# AC30M1X64 register map
Vendor: ABOV Semiconductor Co., Ltd.; File version: 1.0.0
CPU: CM0 r1p0, little endian, no MPU, no FPU, 2 interrupt priority bits
Registers are 32-bit, read-write, reset 0x0 unless marked. A register's access mark holds for its fields unless they carry their own. Offsets are from the block's base; [hi:lo] are bit positions; {n}, {i} and the like mark numbered series; 'fields as' and 'values as' point back to an identical list.

## SP — SERIAL PERIPHERAL INTERFACE
Base 0x40009000
0x00 RDR ro (reset mask 0xFFFF) — SPI n Receive Data Register
  [16:0] RDR — Data
0x00 TDR wo (reset mask 0xFFFF) — SPI n Transmit Data Register
  [16:0] TDR — Data
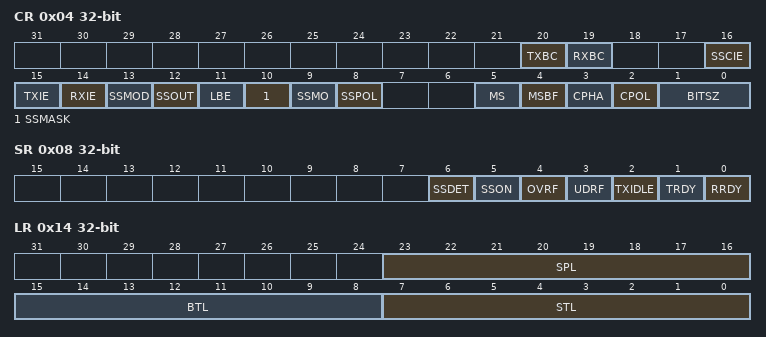
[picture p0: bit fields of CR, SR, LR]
0x04 CR — SPI n Control Register
  [20] TXBC — Tx buffer clear bit
  [19] RXBC — Rx buffer clear bit
  [16] SSCIE — SSn Edge Change Interrupt enable bit
  [15] TXIE — Transmit interrupt enable bit
  [14] RXIE — Receive interrupt enable bit
  [13] SSMOD — SS Auto/Manual Output select bit
  [12] SSOUT — SS output signal select bit
  [11] LBE — Loop-back mode select bit in master mode
  [10] SSMASK — SS Signal masking bit in slave mode
  [9] SSMO — SS output signal select bit
  [8] SSPOL — SS Signal polarity select bit
  [5] MS — master/slaver select bit
  [4] MSBF — MSB/LSB transmit select bit
  [3] CPHA — SPI clock phase bit
  [2] CPOL — SPI clock polarity bit
  [1:0] BITSZ — Transmit/receive Data bits select bit
0x08 SR — SPI n Status Register
  [6] SSDET — The rising edge of SS detect flag
  [5] SSON — SS signal status flag
  [4] OVRF — receive overrun error flag
  [3] UDRF — transmit underrun error flag
  [2] TXIDLE ro — transmit/receive operation flag
  [1] TRDY ro — Transmit buffer empty flag
  [0] RRDY ro — receive buffer ready flag
0x0C BR — SPI n Baud Rate Register
  [15:0] BR — buadrate
0x10 EN — SPI n Enable register
  [0] ENABLE — SPI ENABLE bit
0x14 LR — SPI n delay Length Register
  [23:16] SPL — Stop delay length
  [15:8] BTL — Burst delay length
  [7:0] STL — Start delay length

## IC — IIC Interface
Base 0x4000A000
0x00 DR — IIC Data Register
  [7:0] DR — Data
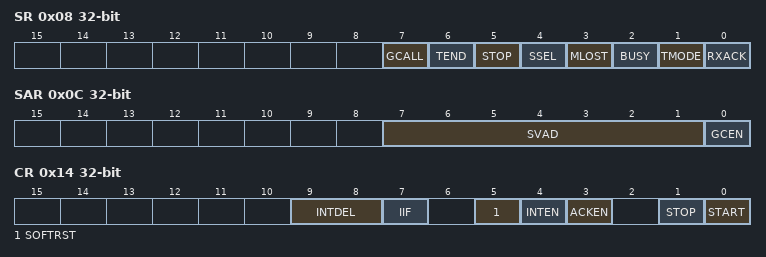
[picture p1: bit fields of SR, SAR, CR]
0x08 SR — Status register
  [7] GCALL — General call flag
  [6] TEND — 1 byte transmission complete flag
  [5] STOP — Stop Flag
  [4] SSEL — slave flag
  [3] MLOST — Mastership lost flag
  [2] BUSY — busy flag
  [1] TMODE — Transmit/reciever mode flag
  [0] RXACK — RX ack flag
0x0C SAR — IIC Slave Address Register
  [7:1] SVAD — 7 bits slave address
  [0] GCEN — general call enable bit
0x14 CR — IIC Control Register
  [9:8] INTDEL — Interval delay value between address and data transfer
  [7] IIF — Interrupt flag bit
  [5] SOFTRST — Soft reset enable bit
  [4] INTEN — Interrupt enable bit
  [3] ACKEN — ACK enabit bit in receiver mode
  [1] STOP — Stop enable bit
  [0] START — transmission start bit in master mode
0x18 SCLL reset 0xFFFF — IIC SCL LOW duration Register
  [15:0] SCLL — SCL Low duration value
0x1C SCLH reset 0xFFFF — IIC SCL HIGH duration Register
  [15:0] SCLH — SCL High duration value
0x20 SDH (reset mask 0x7F) — SDA Hold Register
  [14:0] SDH — SDA Hold time

## MP — MOTOR PULSE-WIDTH-MODULATOR
Base 0x40004000
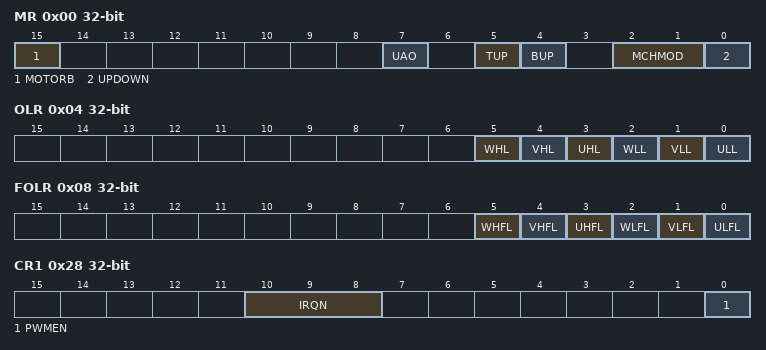
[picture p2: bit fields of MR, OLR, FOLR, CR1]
0x00 MR — MPWM Mode Register
  [15] MOTORB
  [7] UAO
  [5] TUP
  [4] BUP
  [2:1] MCHMOD
  [0] UPDOWN — PWM counter mode
0x04 OLR — MPWM Port Mode Register
  [5] WHL, [4] VHL, [3] UHL, [2] WLL, [1] VLL, [0] ULL
0x08 FOLR — MPWM Force Output Level Register
  [5] WHFL, [4] VHFL, [3] UHFL, [2] WLFL, [1] VLFL, [0] ULFL
0x0C PRD — MPWM Period Register
  [15:0] PERIOD — PWM period
0x10 DUH — MPWM Duty UH Register
  [15:0] DUTY — duty of UH output
0x14 DVH — MPWM Duty VH Register
  [15:0] DUTY — duty of VH data
0x18 DWH — MPWM Duty WH Register
  [15:0] DUTY — duty of WH output
0x1C DUL — MPWM Duty UL Register
  [15:0] DUTY — duty of UL output
0x20 DVL — MPWM Duty UL Register
  [15:0] DUTY — duty of VL output
0x24 DWL — MPWM Duty WL Register
  [15:0] DUTY — duty of WL output
0x28 CR1 — MPWM Control Register 1
  [10:8] IRQN — IRQ intervel Number
  [0] PWMEN
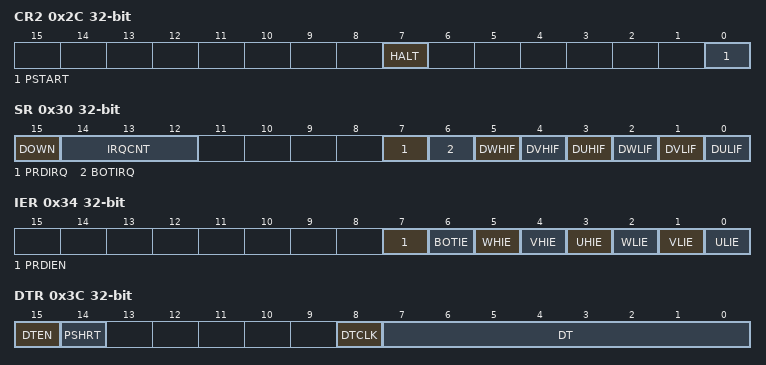
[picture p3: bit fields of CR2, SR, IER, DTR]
0x2C CR2 — MPWM Control Register 2
  [7] HALT
  [0] PSTART — PWM start
0x30 SR — MPWM Status Register
  [15] DOWN — PWM count up/down
  [14:12] IRQCNT — PWM count number of period match
  [7] PRDIRQ — PWM period interrupt flag
  [6] BOTIRQ — PWM bottom interrupt flag
  [5] DWHIF
  [4] DVHIF
  [3] DUHIF
  [2] DWLIF
  [1] DVLIF
  [0] DULIF
0x34 IER — MPWM Interrupt Enable Register
  [7] PRDIEN — Period interrupt enable
  [6] BOTIE — bottom interrupt enable
  [5] WHIE
  [4] VHIE
  [3] UHIE
  [2] WLIE
  [1] VLIE
  [0] ULIE
0x38 CNT — MPWM Counter Register
  [15:0] CNT — pwm counter value
0x3C DTR — MPWM Dead Time Register
  [15] DTEN — dead time Enable
  [14] PSHRT
  [8] DTCLK — dead time clk select
  [7:0] DT — dead time value
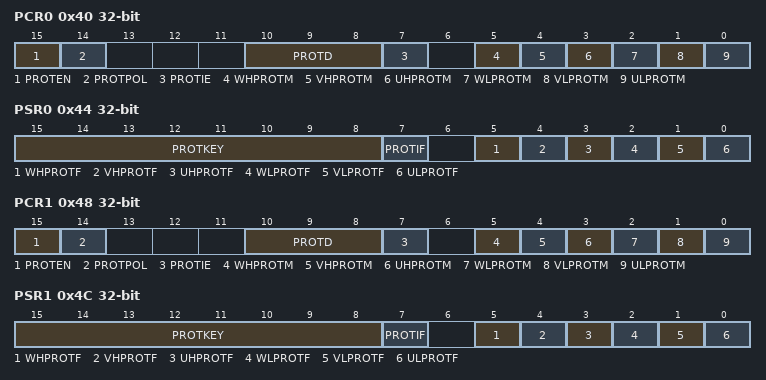
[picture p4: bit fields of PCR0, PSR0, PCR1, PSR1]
0x40 PCR0 — MPWM Protection control Register 0
  [15] PROTEN, [14] PROTPOL, [10:8] PROTD, [7] PROTIE, [5] WHPROTM, [4] VHPROTM, [3] UHPROTM, [2] WLPROTM, [1] VLPROTM, [0] ULPROTM
0x44 PSR0 — MPWM Protection Status Register 0
  [15:8] PROTKEY — PROTKEY(0xCA)
  [7] PROTIF
  [5] WHPROTF
  [4] VHPROTF
  [3] UHPROTF
  [2] WLPROTF
  [1] VLPROTF
  [0] ULPROTF
0x48 PCR1 — MPWM Protection control Register 1
  fields as PCR0
0x4C PSR1 — MPWM Protection Status Register 1
  [15:8] PROTKEY — PROTKEY(0xAC)
  [7] PROTIF
  [5] WHPROTF
  [4] VHPROTF
  [3] UHPROTF
  [2] WLPROTF
  [1] VLPROTF
  [0] ULPROTF
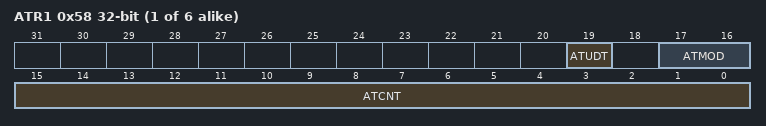
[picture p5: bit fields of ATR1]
{0x54+4i} ATR{i} (i=1..6) — MPWMn ADC Trigger Counter {i} Register
  [19] ATUDT — Trigger register update mode
  [17:16] ATMOD — ADC Trigger mode register
  [15:0] ATCNT — ADC Trigger counter

## DIV64 — DIVIDER
Base 0x40000500
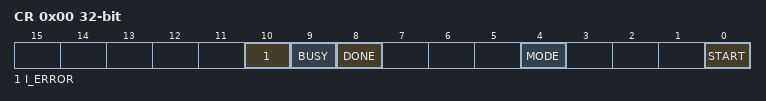
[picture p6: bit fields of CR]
0x00 CR — Divider Control Register
  [10] I_ERROR — Divide by zero flag
  [9] BUSY — Divider is now under operating
  [8] DONE — Divider operation done flag
  [4] MODE — Start operation mode
  [0] START — Divide operation start command.
0x04 AREGL — AREGL (Dividend) Low 32bit Register
0x08 AREGH — AREG (Dividend) High 32bit Register
0x0C BREG — BREG (Divisor) Register
0x10 QREGL — QREG (Quotient) Low 32bit Register
0x14 QREGH — QREG (Quotient) High 32bit Register
0x18 RREG — RREG (Remainter) Register

## AD — 12-BIT A/D CONVERTER
Base 0x4000B000
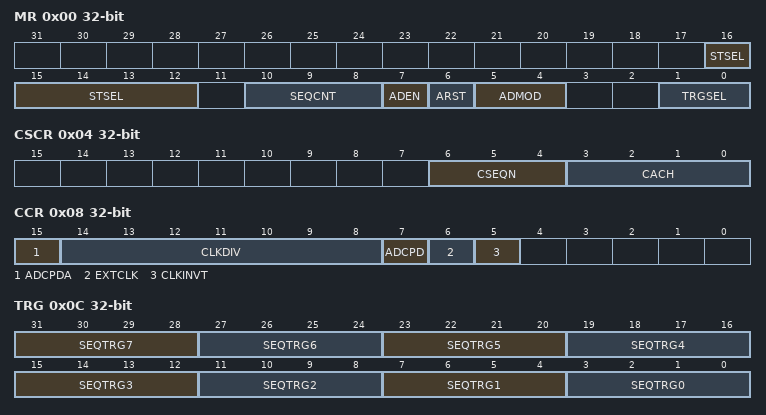
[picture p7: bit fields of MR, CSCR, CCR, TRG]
0x00 MR — ADC Mode Register
  [16:12] STSEL
  [10:8] SEQCNT
  [7] ADEN — ADC Enable
  [6] ARST
  [5:4] ADMOD — ADC convert mode
  [1:0] TRGSEL
0x04 CSCR — Current Sequence/Channel Register
  [6:4] CSEQN
  [3:0] CACH — Current Active Channel
0x08 CCR — Clock Control Register
  [15] ADCPDA — ADC R-ADC disable to save power
  [14:8] CLKDIV — ADC clock divider
  [7] ADCPD — ADC Power down
  [6] EXTCLK — ADCuse external clock
  [5] CLKINVT — divided clock inversion
0x0C TRG — ADC Trigger Selection Register
  [4n+3:4n] SEQTRG{n} (n=3..7) — {n+1}th Sequence Trigger Source
  [11:8] SEQTRG2 — 3rd Sequence Trigger Source
  [7:4] SEQTRG1 — 2nd Sequence Trigger Source
  [3:0] SEQTRG0 — 1st Sequence Trigger Source
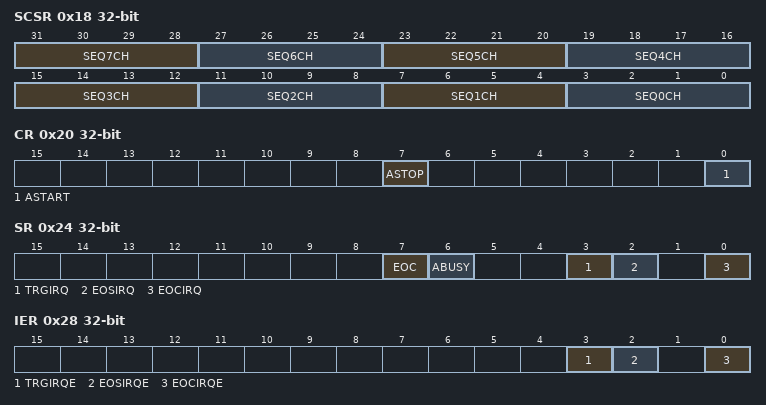
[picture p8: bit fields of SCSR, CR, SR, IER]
0x18 SCSR — ADC Sequence Channel Selection Register
  [4n+3:4n] SEQ{n}CH (n=3..7) — {n+1}th conversion sequence channel selection
  [11:8] SEQ2CH — 3rd conversion sequence channel selection
  [7:4] SEQ1CH — 2nd conversion sequence channel selection
  [3:0] SEQ0CH — 1st conversion sequence channel selection
0x20 CR — ADCn Control Register
  [7] ASTOP wo — ADC Stop
  [0] ASTART — ADC conversion start
0x24 SR — ADCn Status Register
  [7] EOC — ADC End Flag
  [6] ABUSY — ADC conversion busy flag
  [3] TRGIRQ — ADC Trigger interrupt flag
  [2] EOSIRQ
  [0] EOCIRQ
0x28 IER — Interrupt Enable Register
  [3] TRGIRQE — ADC trigger conversion interrupt enable
  [2] EOSIRQE — ADC sequence conversion interrupt enable
  [0] EOCIRQE — ADC single conversion interrupt enable
{0x30+4i} DR{i} (i=0..7) — ADC Data Register {i}
  [15:4] ADCDATA — ADC conversion result data
